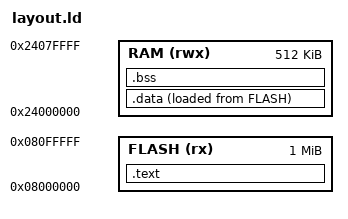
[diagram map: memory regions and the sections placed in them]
MEMORY
{
    FLASH (rx) : ORIGIN = 0x08000000, LENGTH = 1024K
    RAM (rwx)  : ORIGIN = 0x24000000, LENGTH = 512K
}

SECTIONS
{
    .text :
    {
        KEEP(*(.isr_vector))
        *(.text*)
        *(.rodata*)
        . = ALIGN(4);
        _etext = .;
    } > FLASH

    /* Used by startup to copy data from FLASH to RAM */
    _sidata = LOADADDR(.data);

    .data :
    {
        _sdata = .;
        *(.data*)
        . = ALIGN(4);
        _edata = .;
    } > RAM AT > FLASH

    .bss :
    {
        _sbss = .;
        *(.bss*)
        *(COMMON)
        . = ALIGN(4);
        _ebss = .;
    } > RAM

    _estack = ORIGIN(RAM) + LENGTH(RAM);
}
